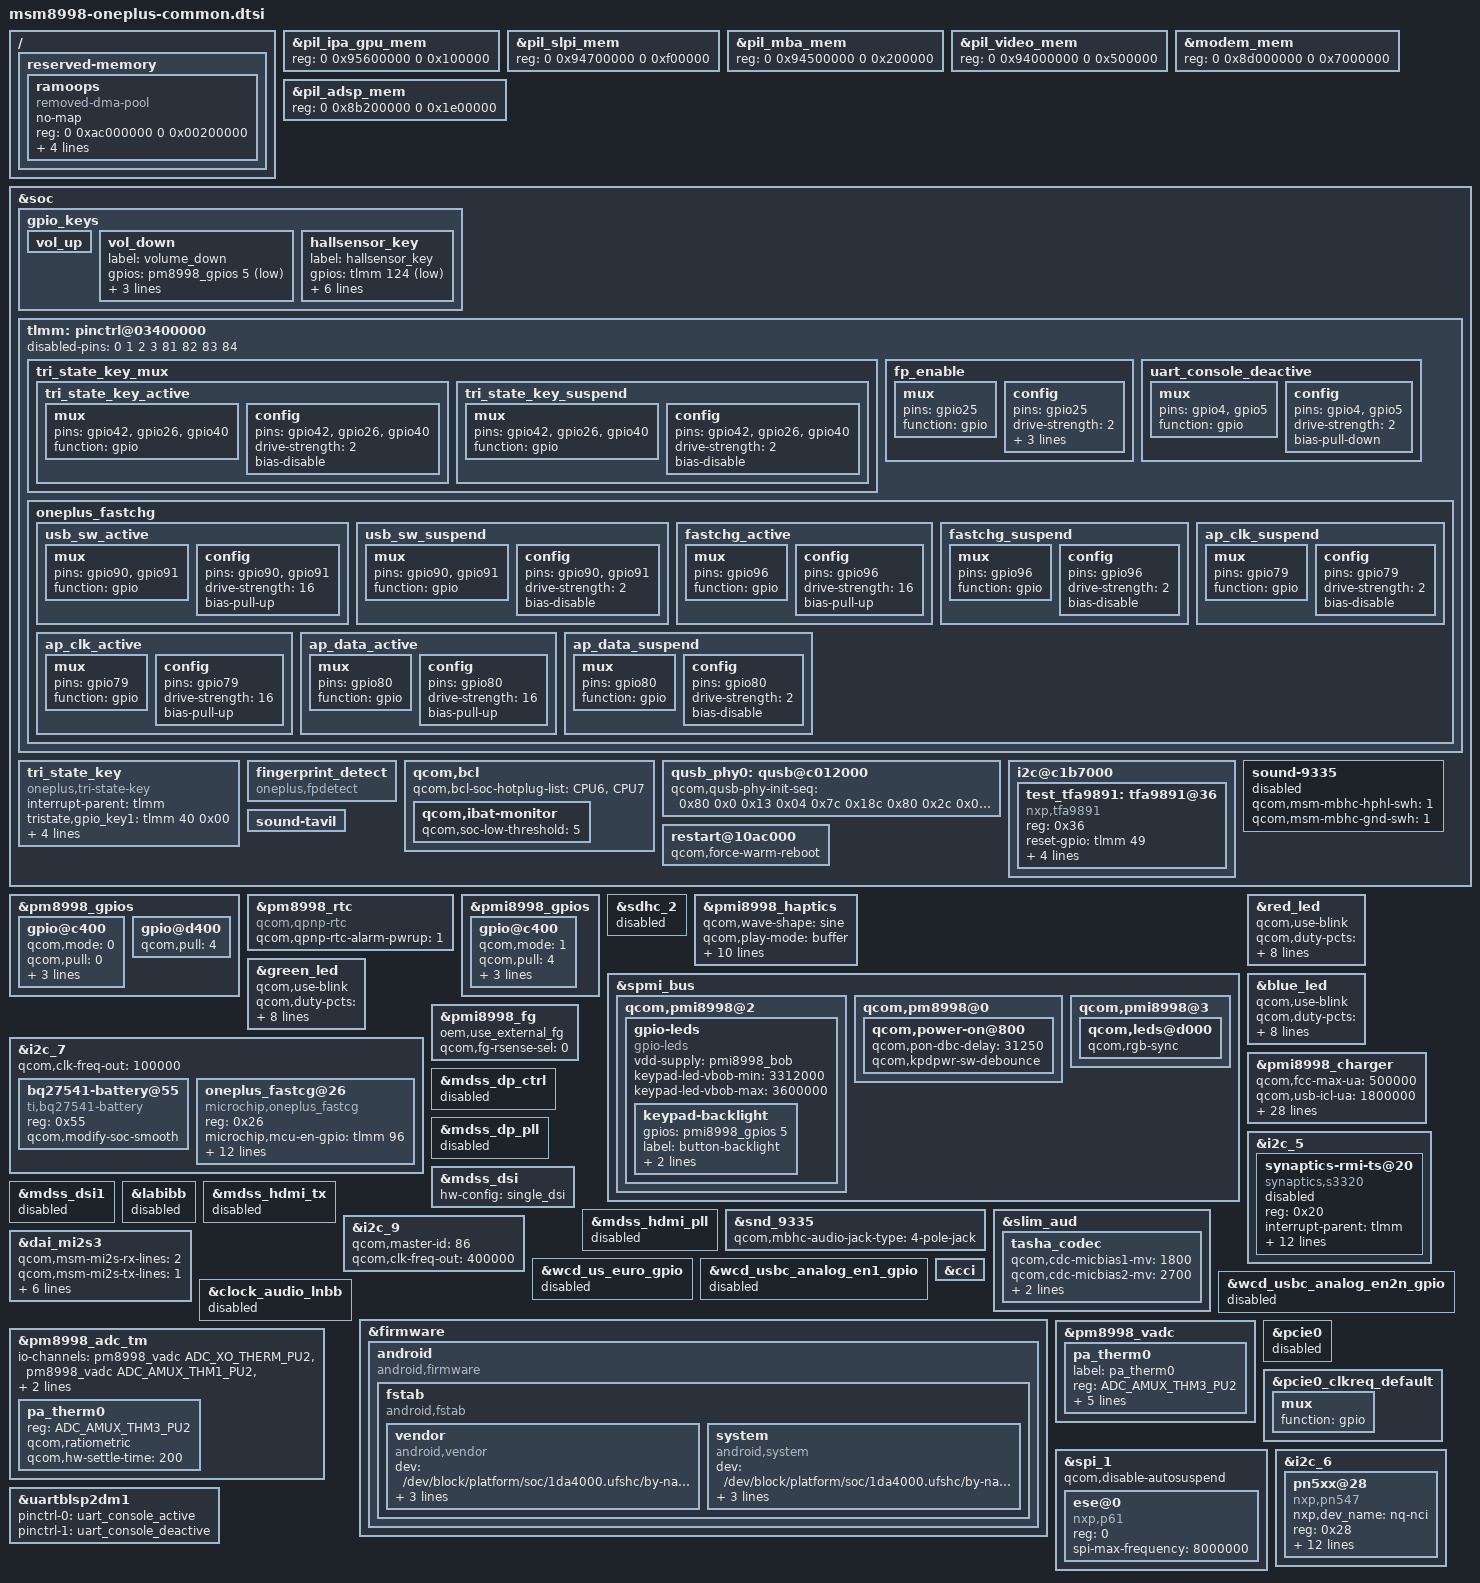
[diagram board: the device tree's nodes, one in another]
/* Copyright (c) 2016-2017, The Linux Foundation. All rights reserved.
 *
 * This program is free software; you can redistribute it and/or modify
 * it under the terms of the GNU General Public License version 2 and
 * only version 2 as published by the Free Software Foundation.
 *
 * This program is distributed in the hope that it will be useful,
 * but WITHOUT ANY WARRANTY; without even the implied warranty of
 * MERCHANTABILITY or FITNESS FOR A PARTICULAR PURPOSE.  See the
 * GNU General Public License for more details.
 */
/*
 * Copyright (c) 2023, Edrick Vince Sinsuan <sedrickvince@gmail.com>
 *
 * This program is free software; you can redistribute it and/or modify
 * it under the terms of the GNU General Public License version 2, as
 * published by the Free Software Foundation.
 */

#include "pxlw-iris-settings.dtsi"

/* Include thermal */
#include "msm8998-oneplus-common-thermal.dtsi"

/* Disable SMP2P Remote Debug for production */
#include "msm-rdbg-disable.dtsi"

/ {
	reserved-memory {
		ramoops {
			compatible = "removed-dma-pool", "ramoops";
			no-map;
			reg = <0 0xac000000 0 0x00200000>;
			record-size = <0x10000>;
			console-size = <0x60000>;
			ftrace-size = <0x10000>;
			pmsg-size = <0x20000>;
			status = "okay";
		};
	};
};

/* Move start address +4M to match modem aligned */
&pil_ipa_gpu_mem {
    reg = <0 0x95600000 0 0x100000>;
};

&pil_slpi_mem {
    reg = <0 0x94700000 0 0xf00000>;
};

&pil_mba_mem {
    reg = <0 0x94500000 0 0x200000>;
};

&pil_video_mem {
    reg = <0 0x94000000 0 0x500000>;
};

&modem_mem {
    reg = <0 0x8d000000 0 0x7000000>;
};

&pil_adsp_mem {
    reg = <0 0x8b200000 0 0x1e00000>;
};

/* I/O */
&soc {
	gpio_keys {
		vol_up {
			/delete-property/ gpio-key,wakeup;
		};

		vol_down {
			label = "volume_down";
			gpios = <&pm8998_gpios 5 0x1>;
			linux,input-type = <1>;
			linux,code = <114>;
			debounce-interval = <15>;
		};

		hallsensor_key {
			label = "hallsensor_key";
			gpios = <&tlmm 124 1>;
			interrupt-parent = <&tlmm>;
			interrupts = <124 0x0>;
			linux,input-type = <5>;
			linux,code = <0>;
			gpio-key,wakeup;
			debounce-interval = <15>;
		};
	};

	pinctrl@03400000 {
		disabled-pins = <0 1 2 3 81 82 83 84>;

		tri_state_key_mux {
			tri_state_key_active: tri_state_key_active {
				mux {
					pins = "gpio42","gpio26","gpio40";
					function = "gpio";
				};

				config {
					pins = "gpio42","gpio26","gpio40";
					drive-strength = <2>;
					bias-disable;
				};
			};

			tri_state_key_suspend: tri_state_key_suspend {
				mux {
					pins = "gpio42","gpio26","gpio40";
					function = "gpio";
				};

				config {
					pins = "gpio42","gpio26","gpio40";
					drive-strength = <2>;
					bias-disable;
				};
			};
		};
	};

	/* Tri-state key */
	tri_state_key {
		compatible = "oneplus,tri-state-key";
		status = "okay";
		interrupt-parent = <&tlmm>;
		tristate,gpio_key1 = <&tlmm 40 0x00>;
		tristate,gpio_key2 = <&tlmm 42 0x00>;
		tristate,gpio_key3 = <&tlmm 26 0x00>;
		pinctrl-names = "pmx_tri_state_key_active", 
				"pmx_tri_state_key_suspend";
		pinctrl-0 = <&tri_state_key_active>;
		pinctrl-1 = <&tri_state_key_suspend>;
	};

	/delete-node/ qcom,qbt1000;

	/* Fingerprint */
	pinctrl@03400000 {
		fp_enable: fp_enable {
			mux {
				pins = "gpio25";
				function = "gpio";
			};

			config {
				pins = "gpio25";
				drive-strength = <2>;
				bias-pull-up;
				output-enable;
				output-high;
			};
		};
	};

	fingerprint_detect {
		compatible = "oneplus,fpdetect";
	};

	qcom,bcl {
		qcom,bcl-soc-hotplug-list = <&CPU6 &CPU7>;
		qcom,ibat-monitor {
			qcom,soc-low-threshold = <5>;
		};
	};

	/* Add  0x9c 0x21C, 0xf0 0x23C */
	qusb_phy0: qusb@c012000 {
		qcom,qusb-phy-init-seq =
				/* <value reg_offset> */
					<0x80 0x0
					0x13 0x04
					0x7c 0x18c
					0x80 0x2c
					0x0a 0x184
					0x9c 0x21C
					0xf0 0x23C
					0x0f 0x240>;
	};

	pinctrl@03400000 {
		uart_console_deactive: uart_console_deactive {
			mux {
				pins = "gpio4", "gpio5";
				function = "gpio";
			};

			config {
				pins = "gpio4", "gpio5";
				drive-strength = <2>;
				bias-pull-down;
			};
		};
	};
};

&pm8998_gpios {
	/* GPIO 5 for Vol- Key */
	gpio@c400 {
		status = "okay";
		qcom,mode = <0>;
		qcom,pull = <0>;
		qcom,vin-sel = <0>;
		qcom,src-sel = <0>;
		qcom,out-strength = <1>;
	};
};

&pm8998_rtc {
	compatible = "qcom,qpnp-rtc";
	qcom,qpnp-rtc-alarm-pwrup = <1>;
};

&pmi8998_gpios {
	/* button-backlight */
	gpio@c400 {
		qcom,mode = <1>;		/* Output */
		qcom,pull = <4>;		/* Pull Down */
		qcom,master-en = <1>;		/* Enable GPIO */
		qcom,invert = <1>;
		qcom,out-strength = <1>;
		status = "okay";
	};
};

&sdhc_2 {
	status = "disabled";
};

&pmi8998_haptics {
	status = "okay";
	qcom,wave-shape = "sine";
	qcom,play-mode = "buffer";
	qcom,wave-samples = <0x28 0x28 0x28 0x28 0x28 0x28 0x28 0x28>;
	qcom,brake-pattern = <0x3 0x3 0x3 0x3>;
	qcom,wave-rep-cnt = <1>;
	qcom,wave-samp-rep-cnt = <1>;
	qcom,use-play-irq;
	qcom,wave-play-rate-us = <4255>;
	qcom,lra-auto-res-mode = "qwd";
	qcom,lra-res-cal-period = <32>;
	qcom,lra-auto-mode;
};

&spmi_bus {
	qcom,pmi8998@2 {
		/* button-backlight */
		gpio-leds {
			compatible = "gpio-leds";
			status = "okay";
			vdd-supply = <&pmi8998_bob>;
			keypad-led-vbob-min = <3312000>;
			keypad-led-vbob-max = <3600000>;
			keypad-backlight {
				/* Here maybe pm8998_gpios, depends on what you use. */
				gpios = <&pmi8998_gpios 5 0>;
				label = "button-backlight";
				linux,default-trigger = "none";
				default-state = "off";
			};
		};
	};

	/* shankai@bsp, add debounce time 2017-3-18 */
	qcom,pm8998@0 {
		qcom,power-on@800 {
		    qcom,pon-dbc-delay = <31250>;
		    qcom,kpdpwr-sw-debounce;
	    };
	};

	qcom,pmi8998@3 {
		qcom,leds@d000 {
			qcom,rgb-sync;
		};
	};
};

&red_led {
	qcom,use-blink;
	qcom,duty-pcts = [00 05 0a 0f 14 1d 28 32 3c 4b 64];
	qcom,duty-ms = <20>;
	qcom,start-idx = <1>;
	qcom,idx-len = <11>;
	qcom,lut-flags = <0x1f>;
	qcom,ramp-step-ms = <100>;
	qcom,pause-lo = <2000>;
	qcom,pause-hi = <1000>;
	/delete-property/ linux,default-trigger;
};

&green_led {
	qcom,use-blink;
	qcom,duty-pcts = [00 05 0a 0f 14 1d 28 32 3c 4b 64];
	qcom,duty-ms = <20>;
	qcom,start-idx = <13>;
	qcom,idx-len = <11>;
	qcom,lut-flags = <0x1f>;
	qcom,ramp-step-ms = <100>;
	qcom,pause-lo = <2000>;
	qcom,pause-hi = <1000>;
	/delete-property/ linux,default-trigger;
};

&blue_led {
	qcom,use-blink;
	qcom,duty-pcts = [00 05 0a 0f 14 1d 28 32 3c 4b 64];
	qcom,duty-ms = <20>;
	qcom,start-idx = <13>;
	qcom,idx-len = <11>;
	qcom,lut-flags = <0x1f>;
	qcom,ramp-step-ms = <100>;
	qcom,pause-lo = <2000>;
	qcom,pause-hi = <1000>;
	/delete-property/ linux,default-trigger;
};

/* Charging */
&soc {
	tlmm: pinctrl@03400000 {
		oneplus_fastchg {
			usb_sw_active: usb_sw_active {
				mux {
					pins = "gpio90", "gpio91";
					function = "gpio";
				};

				config {
					pins = "gpio90", "gpio91";
					drive-strength = <16>;
					bias-pull-up;
				};
			};

			usb_sw_suspend: usb_sw_suspend {
				mux {
					pins = "gpio90", "gpio91";
					function = "gpio";
				};

				config {
					pins = "gpio90", "gpio91";
					drive-strength = <2>;
					bias-disable;
				};
			};

			fastchg_active: fastchg_active {
				mux {
					pins = "gpio96";
					function = "gpio";
				};

				config {
					pins = "gpio96";
					drive-strength = <16>;
					bias-pull-up;
				};
			};

			fastchg_suspend: fastchg_suspend {
				mux {
					pins = "gpio96";
					function = "gpio";
				};

				config {
					pins = "gpio96";
					drive-strength = <2>;
					bias-disable;
				};
			};

			ap_clk_active: ap_clk_active {
				mux {
					pins = "gpio79";
					function = "gpio";
				};

				config {
					pins = "gpio79";
					drive-strength = <16>;
					bias-pull-up;
				};
			};

			ap_clk_suspend: ap_clk_suspend {
				mux {
					pins = "gpio79";
					function = "gpio";
				};

				config {
					pins = "gpio79";
					drive-strength = <2>;
					bias-disable;
				};
			};

			ap_data_active: ap_data_active {
				mux {
					pins = "gpio80";
					function = "gpio";
				};

				config {
					pins = "gpio80";
					drive-strength = <16>;
					bias-pull-up;
				};
			};

			ap_data_suspend: ap_data_suspend {
				mux {
					pins = "gpio80";
					function = "gpio";
				};

				config {
					pins = "gpio80";
					drive-strength = <2>;
					bias-disable;
				};
			};
		};
	};
};

&i2c_7 {
	qcom,clk-freq-out = <100000>;

	bq27541-battery@55 {
		status = "ok";
		compatible = "ti,bq27541-battery";
		reg = <0x55>;
		qcom,modify-soc-smooth;
	};

	oneplus_fastcg@26 {
		status = "ok";
		compatible = "microchip,oneplus_fastcg";
		reg = <0x26>;
		microchip,mcu-en-gpio = <&tlmm 96 0x00>;
		microchip,usb-sw-1-gpio = <&tlmm 90 0x00>;
		microchip,usb-sw-2-gpio = <&tlmm 91 0x00>;
		microchip,ap-clk = <&tlmm 79 0x00>;
		microchip,ap-data = <&tlmm 80 0x00>;
		pinctrl-names = "mux_fastchg_active",
				"mux_fastchg_suspend",
				"mcu_data_active",
				"mcu_data_suspend";
		pinctrl-0 = <&fastchg_active
		&usb_sw_active
		&ap_clk_active >;
		pinctrl-1 = <&usb_sw_suspend
				&fastchg_suspend
				&ap_clk_suspend>;
		pinctrl-2 = <&ap_data_active>;
		pinctrl-3 = <&ap_data_suspend>;
		clocks = <&clock_rpmcc UART_SNOC_MSMBUS_A_CLK>,
			<&clock_rpmcc UART_CNOC_MSMBUS_A_CLK>;
		clock-names = "snoc", "cnoc";
	};
};

&pmi8998_charger {
	/* Set FCC MAX 500mA by default, FCC will */
	/* be set again after check battery temperature */
	qcom,fcc-max-ua = <500000>;
	qcom,usb-icl-ua = <1800000>;
	qcom,fv-max-uv = <4365000>;
	/* ibatmax setting for different temp regions */
	ibatmax-little-cold-ma = <325>;
	ibatmax-cool-ma = <450>;
	ibatmax-little-cool-ma = <775>;
	ibatmax-pre-normal-ma = <1425>;
	ibatmax-normal-ma = <1950>;
	ibatmax-warm-ma = <750>;
	/* vbatmax setting for different temp regions */
	vbatmax-little-cold-mv = <3975>; //3980
	vbatmax-cool-mv = <4380>;
	vbatmax-little-cool-mv = <4380>;
	vbatmax-pre-normal-mv = <4380>;
	vbatmax-normal-mv = <4380>;
	vbatmax-warm-mv = <4080>;
	/* vbatdet setting for different temp regions */
	vbatdet-little-cold-mv = <3700>;
	vbatdet-cool-mv = <4150>;
	vbatdet-little-cool-mv = <4270>;
	vbatdet-pre-normal-mv = <4270>;
	vbatdet-normal-mv = <4270>;
	vbatdet-warm-mv = <3980>;
	/* temp region settings */
	cold-bat-decidegc = <30>;
	little-cold-bat-decidegc = <0>;
	cool-bat-decidegc = <50>;
	little-cool-bat-decidegc = <120>;
	pre-normal-bat-decidegc = <160>;
	warm-bat-decidegc = <450>;
	hot-bat-decidegc = <530>;
	/* other settings */
	qcom,cutoff-voltage-with-charger = <3250>;
	disable-pd;
};

&pmi8998_fg {
	oem,use_external_fg;
	qcom,fg-rsense-sel = <0>;
};

/* Display */
&i2c_5 {
	/delete-node/ synaptics@20;

	synaptics-rmi-ts@20 {
		status = "disabled";
		compatible = "synaptics,s3320";
		reg = <0x20>;
		interrupt-parent = <&tlmm>;
		interrupts = <125 0x2008>;
		vcc_i2c_1v8-supply = <&pm8998_l6>;
		vdd_2v8-supply = <&pm8998_l28>;
		synaptics,vdd-voltage = <1808000 1808000>;
		synaptics,avdd-voltage = <3008000 3008000>;
		synaptics,vdd-current = <40000>;
		synaptics,avdd-current = <20000>;
		synaptics,reset-gpio = <&tlmm 89 0x00>;
		synaptics,irq-gpio = <&tlmm 125 0x2008>;
		oem,support_hw_poweroff;
		pinctrl-names = "pmx_ts_active", "pmx_ts_suspend";
		pinctrl-0 = <&ts_active>;
		pinctrl-1 = <&ts_int_suspend &ts_reset_suspend>;
	};
};

&mdss_dp_ctrl {
	status = "disabled";
};

&mdss_dp_pll {
	status = "disabled";
};

&mdss_dsi {
	hw-config = "single_dsi";
};

&mdss_dsi1 {
	status = "disabled";
	/delete-property/ qcom,dsi-pref-prim-pan;
};

&labibb {
	status = "disabled";
};

&mdss_hdmi_tx {
	status = "disabled";
};

&mdss_hdmi_pll {
	status = "disabled";
};

/* Audio */
&snd_9335 {
	qcom,mbhc-audio-jack-type = "4-pole-jack";
};

/*
 * liuhaituo@MultiMediaAudio modified for adapation phone
 * headset and AKG headset-mic 2018/4/26
 */
&slim_aud {
	tasha_codec {
		qcom,cdc-micbias1-mv = <1800>;
		qcom,cdc-micbias2-mv = <2700>;
		qcom,cdc-micbias3-mv = <1800>;
		qcom,cdc-micbias4-mv = <1800>;

		/* These nodes' GPIOs are taken by goodix_fp and mdss_dsi0 */
		/delete-node/ msm_cdc_pinctrll;
		/delete-node/ msm_cdc_pinctrlr;		
		/delete-node/ swr_master;
	};
};

&soc {
	i2c@c1b7000 {
		status = "ok";
		test_tfa9891: tfa9891@36 {
			status = "ok";
			compatible = "nxp,tfa9891";
			reg = <0x36>;
			reset-gpio= <&tlmm 49 0>;
			irq-gpio= <&tlmm 50 0>;
			bob_power-supply = <&pmi8998_bob>;
			qcom,bob_power-voltage-level = <2950000 2960000>;
			qcom,bob_power-current-level = <200 800000>;
		};
	};

	sound-9335 {
		status = "disabled";
		/delete-property/ qcom,us-euro-gpios;
		qcom,msm-mbhc-hphl-swh = <1>;
		qcom,msm-mbhc-gnd-swh = <1>;
		/delete-property/ qcom,wsa-max-devs;
		/delete-property/ qcom,wsa-devs;
		/delete-property/ qcom,wsa-aux-dev-prefix;
	};

	sound-tavil {
		/delete-property/ qcom,usbc-analog-en1_gpio;
		/delete-property/ qcom,usbc-analog-en2_n_gpio;
	};
};

&i2c_9 { /* BLSP2 QUP9 for Audio Speaker */
	qcom,master-id = <86>;
	qcom,clk-freq-out = <400000>;
	status = "ok";
};

&dai_mi2s3 {
	qcom,msm-mi2s-rx-lines = <2>;
	qcom,msm-mi2s-tx-lines = <1>;
	qcom,msm-mi2s-slave = <0>;
	qcom,msm-mi2s-ext-mclk = <0>;
	pinctrl-names = "default", "sleep";
	pinctrl-0 = <&quat_mi2s_active
			&quat_mi2s_sd0_active
			&quat_mi2s_sd1_active>;
	pinctrl-1 = <&quat_mi2s_sleep
			&quat_mi2s_sd0_sleep
			&quat_mi2s_sd1_sleep>;
};

&wcd_us_euro_gpio {
	status = "disabled";
};

&wcd_usbc_analog_en1_gpio {
	status = "disabled";
};

&wcd_usbc_analog_en2n_gpio {
	status = "disabled";
};

&clock_audio_lnbb {
	status = "disabled";
};

/* Camera */
&cci {
	/delete-node/ qcom,camera@1;
};

&firmware {
	android {
		compatible = "android,firmware";
		fstab {
			compatible = "android,fstab";
			vendor {
				compatible = "android,vendor";
				dev = "/dev/block/platform/soc/1da4000.ufshc/by-name/vendor";
				type = "ext4";
				mnt_flags = "ro,barrier=1,discard";
				fsmgr_flags = "wait";
				status = "ok";
			};
			system {
				compatible = "android,system";
				dev = "/dev/block/platform/soc/1da4000.ufshc/by-name/system";
				type = "ext4";
				mnt_flags = "ro,barrier=1,discard";
				fsmgr_flags = "wait";
				status = "ok";
			};
		};
	};
};

/* External Thermistors */
&pm8998_vadc {
	pa_therm0 {
		label = "pa_therm0";
		reg = <ADC_AMUX_THM3_PU2>;
		qcom,decimation = <1024>;
		qcom,pre-scaling = <1 1>;
		qcom,ratiometric;
		qcom,hw-settle-time = <200>;
		qcom,avg-samples = <1>;
	};
};

&pm8998_adc_tm {
	io-channels = <&pm8998_vadc ADC_XO_THERM_PU2>,
		<&pm8998_vadc ADC_AMUX_THM1_PU2>,
		<&pm8998_vadc ADC_AMUX_THM5_PU2>,
		<&pm8998_vadc ADC_AMUX_THM3_PU2>;

	pa_therm0 {
		reg = <ADC_AMUX_THM3_PU2>;
		qcom,ratiometric;
		qcom,hw-settle-time = <200>;
	};
};

/* Disable pcie0 as its wake-gpio is used for NFC */
&pcie0 {
	status = "disabled";
};

&pcie0_clkreq_default {
	mux {
		function = "gpio";
	};
};

&pm8998_gpios {
	gpio@d400 {
		qcom,pull = <4>;
	};
};

&spi_1 {
	status = "ok";
	qcom,disable-autosuspend;

	ese@0 {
		compatible = "nxp,p61";
		reg = <0>;
		spi-max-frequency = <8000000>;
	};
};

&i2c_6 { /* BLSP1 QUP6 (NFC) */
	/delete-node/ nq@28;

	pn5xx@28 {
		compatible = "nxp,pn547";
		nxp,dev_name = "nq-nci";
		reg = <0x28>;
		interrupt-parent = <&tlmm>;
		interrupts = <92 0>;
		nxp,irq_gpio = <&tlmm 92 0x00>;
		nxp,dwld_en = <&tlmm 93 0x00>;
		nxp,ven = <&tlmm 12 0x00>;
		nxp,clk_req = <&pm8998_gpios 21 0x00>;
		nxp,pvdd_en = <&tlmm 37 0x00>;
		nxp,use_pn544;
		clocks = <&clock_rpmcc RPM_SMD_LN_BB_CLK3>;
		clock-names = "nfc_clk";
		pinctrl-names = "pn547-active", "pn547-inactive";
		pinctrl-0 = <&nfc_int_active 
				&nfc_enable_active
				&nfc_clk_default>;
		pinctrl-1 = <&nfc_int_suspend &nfc_enable_suspend>;
	};
};

&uartblsp2dm1 {
	pinctrl-names = "uart_active", "uart_deactive";
	pinctrl-0 = <&uart_console_active>;
	pinctrl-1 = <&uart_console_deactive>;
};

&soc {
	restart@10ac000 {
		qcom,force-warm-reboot;
	};
};
